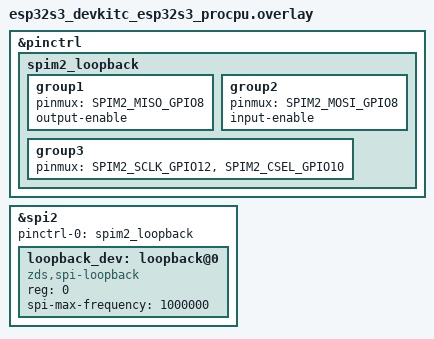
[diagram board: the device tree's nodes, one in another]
/*
 * ESP32-S3-DevKitC-1: SPI2 (GPSPI2) bus-level loopback self-test.
 *
 * No external hardware needed - MISO and MOSI are both routed to the
 * same physical pad (GPIO8) via pinctrl. ESP32-S3's GPIO matrix lets
 * input and output signal routing be configured independently per
 * pad, so the same pin can simultaneously be "SPI2 output" (MOSI,
 * output-enable) and "SPI2 input" (MISO, input-enable): whatever the
 * master drives out on MOSI is immediately read back on MISO,
 * without a jumper wire.
 *
 * SCLK = GPIO12, hardware CS0 = GPIO10 (arbitrary free GPIOs on this
 * board - check the board's pinout for your revision if repurposing
 * these for something else).
 */

&pinctrl {
    spim2_loopback: spim2_loopback {
        group1 {
            pinmux = <SPIM2_MISO_GPIO8>;
            output-enable;
        };
        group2 {
            pinmux = <SPIM2_MOSI_GPIO8>;   /* same GPIO8 as MISO - this is the trick */
            input-enable;
        };
        group3 {
            pinmux = <SPIM2_SCLK_GPIO12>, <SPIM2_CSEL_GPIO10>;
        };
    };
};

&spi2 {
    #address-cells = <1>;
    #size-cells = <0>;
    status = "okay";
    pinctrl-0 = <&spim2_loopback>;
    pinctrl-names = "default";

    loopback_dev: loopback@0 {
        compatible = "zds,spi-loopback";
        reg = <0>;
        spi-max-frequency = <1000000>;
    };
};
